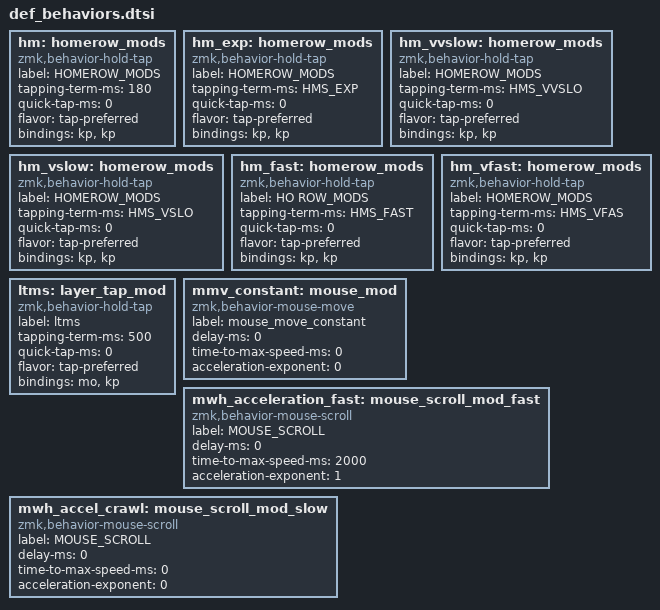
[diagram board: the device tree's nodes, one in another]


            hm: homerow_mods {
                compatible = "zmk,behavior-hold-tap";
                label = "HOMEROW_MODS";
                #binding-cells = <2>;
                tapping-term-ms = <180>;
                quick-tap-ms = <0>;
                flavor = "tap-preferred";
                bindings = <&kp>, <&kp>;
            };
            

            hm_exp: homerow_mods {
                compatible = "zmk,behavior-hold-tap";
                label = "HOMEROW_MODS";
                #binding-cells = <2>;
                tapping-term-ms = <HMS_EXP>;
                quick-tap-ms = <0>;
                flavor = "tap-preferred";
                bindings = <&kp>, <&kp>;
            };
            
            hm_vvslow: homerow_mods {
                    compatible = "zmk,behavior-hold-tap";
                    label = "HOMEROW_MODS";
                    #binding-cells = <2>;
                    tapping-term-ms = <HMS_VVSLO>;
                    quick-tap-ms = <0>;
                    flavor = "tap-preferred";
                    bindings = <&kp>, <&kp>;
            };
            
            hm_vslow: homerow_mods {
                    compatible = "zmk,behavior-hold-tap";
                    label = "HOMEROW_MODS";
                    #binding-cells = <2>;
                    tapping-term-ms = <HMS_VSLO>;
                    quick-tap-ms = <0>;
                    flavor = "tap-preferred";
                    bindings = <&kp>, <&kp>;
            };
            
            hm_fast: homerow_mods {
                    compatible = "zmk,behavior-hold-tap";
                    label = "HO
                    ROW_MODS";
                    #binding-cells = <2>;
                    tapping-term-ms = <HMS_FAST>;
                    quick-tap-ms = <0>;
                    flavor = "tap-preferred";
                    bindings = <&kp>, <&kp>;
            };

            hm_vfast: homerow_mods {
                    compatible = "zmk,behavior-hold-tap";
                    label = "HOMEROW_MODS";
                    #binding-cells = <2>;
                    tapping-term-ms = <HMS_VFAS>;
                    quick-tap-ms = <0>;
                    flavor = "tap-preferred";
                    bindings = <&kp>, <&kp>;
            };

            ltms: layer_tap_mod {
                compatible = "zmk,behavior-hold-tap";
                label = "ltms";
                #binding-cells = <2>;
                tapping-term-ms = <500>;
                quick-tap-ms = <0>;
                flavor = "tap-preferred";
                bindings = <&mo>, <&kp>;
                    };

            mmv_constant: mouse_mod {
                    compatible = "zmk,behavior-mouse-move";
                    label = "mouse_move_constant";
                    #binding-cells = <1>;
                    delay-ms = <0>;
                    time-to-max-speed-ms = <0>;
                    acceleration-exponent = <0>;
            };

            mwh_acceleration_fast: mouse_scroll_mod_fast {
                compatible = "zmk,behavior-mouse-scroll";
                label = "MOUSE_SCROLL";
                #binding-cells = <1>;
                delay-ms = <0>;
                time-to-max-speed-ms = <2000>;
                acceleration-exponent = <1>;
            }; 

            mwh_accel_crawl: mouse_scroll_mod_slow {
                compatible = "zmk,behavior-mouse-scroll";
                label = "MOUSE_SCROLL";
                #binding-cells = <1>;
                delay-ms = <0>;
                time-to-max-speed-ms = <0>;
                acceleration-exponent = <0>;
            };
        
